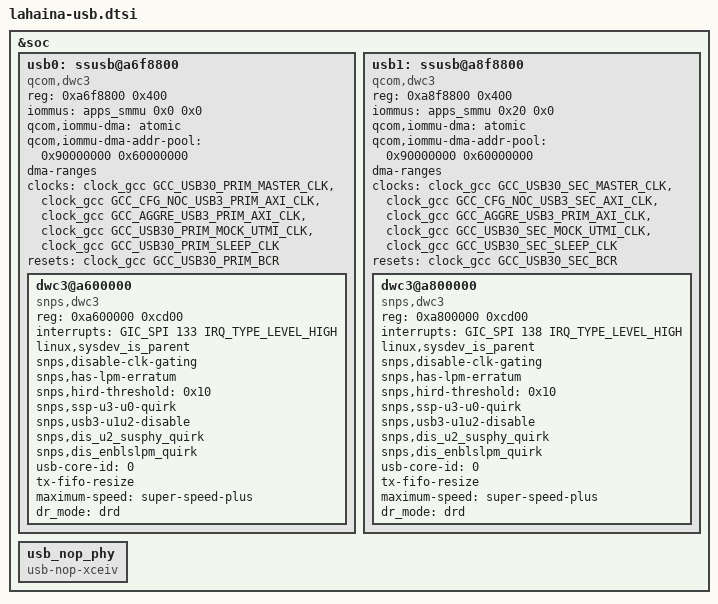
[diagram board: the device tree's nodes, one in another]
&soc {
	usb0: ssusb@a6f8800 {
		compatible = "qcom,dwc3";
		reg = <0xa6f8800 0x400>;
		reg-names = "core_base";

		iommus = <&apps_smmu 0x0 0x0>;
		qcom,iommu-dma = "atomic";
		qcom,iommu-dma-addr-pool = <0x90000000 0x60000000>;
		#address-cells = <1>;
		#size-cells = <1>;
		ranges;
		dma-ranges;

		clocks = <&clock_gcc GCC_USB30_PRIM_MASTER_CLK>,
			<&clock_gcc GCC_CFG_NOC_USB3_PRIM_AXI_CLK>,
			<&clock_gcc GCC_AGGRE_USB3_PRIM_AXI_CLK>,
			<&clock_gcc GCC_USB30_PRIM_MOCK_UTMI_CLK>,
			<&clock_gcc GCC_USB30_PRIM_SLEEP_CLK>;
		clock-names = "core_clk", "iface_clk", "bus_aggr_clk",
					"utmi_clk", "sleep_clk";

		resets = <&clock_gcc GCC_USB30_PRIM_BCR>;
		reset-names = "core_reset";

		dwc3@a600000 {
			compatible = "snps,dwc3";
			reg = <0xa600000 0xcd00>;
			interrupts = <GIC_SPI 133 IRQ_TYPE_LEVEL_HIGH>;
			linux,sysdev_is_parent;
			snps,disable-clk-gating;
			snps,has-lpm-erratum;
			snps,hird-threshold = /bits/ 8 <0x10>;
			snps,ssp-u3-u0-quirk;
			snps,usb3-u1u2-disable;
			snps,dis_u2_susphy_quirk;
			snps,dis_enblslpm_quirk;
			usb-core-id = <0>;
			tx-fifo-resize;
			maximum-speed = "super-speed-plus";
			dr_mode = "drd";
		};
	};

	usb1: ssusb@a8f8800 {
		compatible = "qcom,dwc3";
		reg = <0xa8f8800 0x400>;
		reg-names = "core_base";

		iommus = <&apps_smmu 0x20 0x0>;
		qcom,iommu-dma = "atomic";
		qcom,iommu-dma-addr-pool = <0x90000000 0x60000000>;
		#address-cells = <1>;
		#size-cells = <1>;
		ranges;
		dma-ranges;

		clocks = <&clock_gcc GCC_USB30_SEC_MASTER_CLK>,
			<&clock_gcc GCC_CFG_NOC_USB3_SEC_AXI_CLK>,
			<&clock_gcc GCC_AGGRE_USB3_PRIM_AXI_CLK>,
			<&clock_gcc GCC_USB30_SEC_MOCK_UTMI_CLK>,
			<&clock_gcc GCC_USB30_SEC_SLEEP_CLK>;
		clock-names = "core_clk", "iface_clk", "bus_aggr_clk",
					"utmi_clk", "sleep_clk";

		resets = <&clock_gcc GCC_USB30_SEC_BCR>;
		reset-names = "core_reset";

		dwc3@a800000 {
			compatible = "snps,dwc3";
			reg = <0xa800000 0xcd00>;
			interrupts = <GIC_SPI 138 IRQ_TYPE_LEVEL_HIGH>;
			linux,sysdev_is_parent;
			snps,disable-clk-gating;
			snps,has-lpm-erratum;
			snps,hird-threshold = /bits/ 8 <0x10>;
			snps,ssp-u3-u0-quirk;
			snps,usb3-u1u2-disable;
			snps,dis_u2_susphy_quirk;
			snps,dis_enblslpm_quirk;
			usb-core-id = <0>;
			tx-fifo-resize;
			maximum-speed = "super-speed-plus";
			dr_mode = "drd";
		};
	};

	usb_nop_phy: usb_nop_phy {
		compatible = "usb-nop-xceiv";
	};
};
